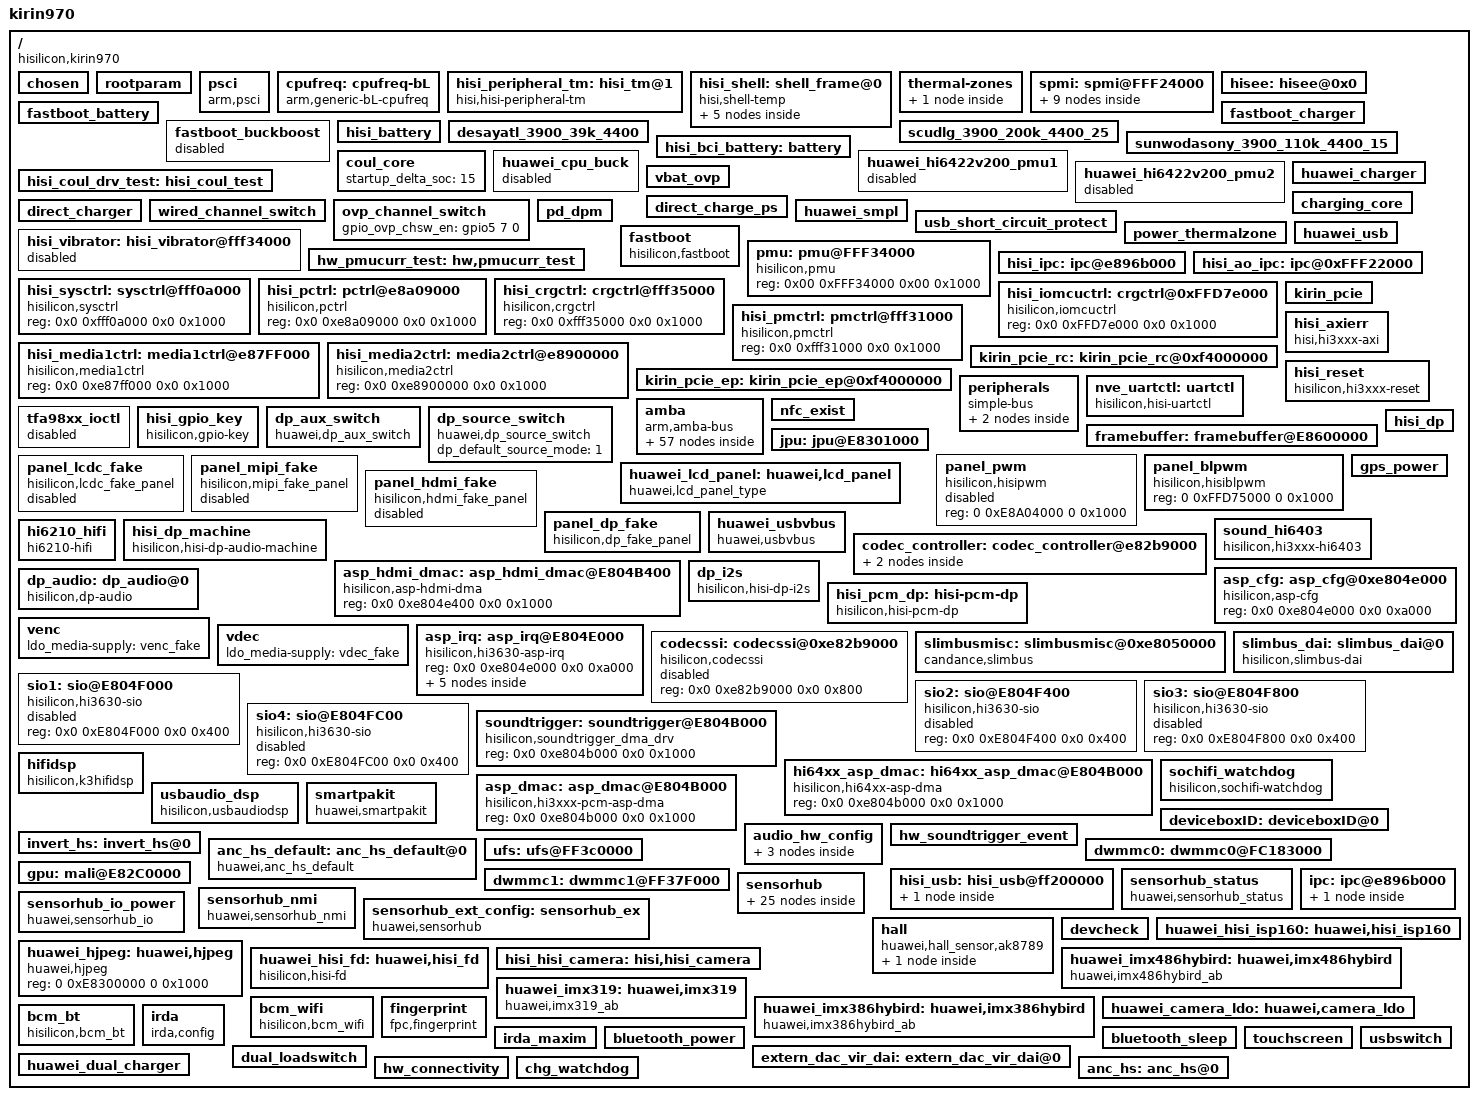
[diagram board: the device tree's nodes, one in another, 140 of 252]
/**
 * Copyright (C) 2014 Hisilicon Ltd.
 *
 *  This program is free software; you can redistribute it and/or modify
 *  it under the terms of the GNU General Public License version 2 as
 *  publishhed by the Free Software Foundation.
 */

/dts-v1/;
/include/ "fastboot.dtsi"
/include/ "ALPS_TUGL_V1_CS_pin.dtsi"
/include/ "kirin970_cci.dtsi"
/include/ "kirin970_gic.dtsi"
/include/ "kirin970_timer.dtsi"
/include/ "kirin970_clock_cs.dtsi"
/include/ "kirin970_peri_dvfs_volt_cs.dtsi"
/include/ "kirin970_peri_dvfs_cs.dtsi"
/include/ "kirin970_isp_cs.dtsi"
/include/ "kirin970_powerip_cs.dtsi"
/include/ "hisi_freq_autodown.dtsi"
/include/ "kirin970.dtsi"
/include/ "kirin970_lowpm.dtsi"
/include/ "kirin970_i2c.dtsi"
/include/ "kirin970_gpio_cs.dtsi"
/include/ "kirin970_pinctrl_cs.dtsi"
/include/ "hisi_64xx_codec.dtsi"
/include/ "ALPS_TUGL_V1_CS_hi6402_pin.dtsi"
/include/ "huawei_pmucurr_test.dtsi"
/include/ "hisi_bci_battery.dtsi"
/include/ "hisi_battery.dtsi"
/include/ "huawei_charger.dtsi"
/include/ "hisi_coul_spmi.dtsi"
/include/ "kirin970_soft_isc.dtsi"
/include/ "fastboot_battery.dtsi"
/include/ "fastboot_charger.dtsi"
/include/ "usb_short_circuit_protect.dtsi"
/include/ "desayatl_3900_39k_4400.dtsi"
/include/ "scudlg_3900_200k_4400_25.dtsi"
/include/ "sunwodasony_3900_110k_4400_15.dtsi"
/include/ "kirin970_thermal.dtsi"
/include/ "kirin970_pd.dtsi"
/include/ "fastboot_charger.dtsi"
/include/ "hisi_power_ip_test.dtsi"
/include/ "kirin970_framebuffer.dtsi"
/include/ "hisi_6421v600_pmic_led_spmi.dtsi"
/include/ "kirin970_coresight.dtsi"
/include/ "hisi_rtc_spmi.dtsi"
/include/ "modem/hisi_modem_balong.dtsi"
/include/ "hisi_soundtrigger_event.dtsi"
/include/ "huawei_audio.dtsi"
/include/ "huawei_smartpa.dtsi"
/include/ "kirin970_noc.dtsi"
/include/ "huawei_gps.dtsi"
/include/ "kirin970_dma64.dtsi"
/include/ "kirin970_trustedcore.dtsi"
/include/ "kirin970_jpu.dtsi"
/include/ "kirin970_ics_cs.dtsi"
/include/ "lcdkit/default/devkit_lcd.dtsi"
/include/ "lcdkit/alps_tugl/devkit_lcd.dtsi"
/include/ "kirin970_perfstat_cs.dtsi"
/include/ "kirin970_cpu_cs.dtsi"
/include/ "huawei_connectivity.dtsi"
/include/ "huawei_devdetect.dtsi"
/include/ "huawei_hall_inputhub.dtsi"
/include/ "huawei_irda.dtsi"
/include/ "huawei_usbpd.dtsi"
/include/ "huawei_usb_vbus.dtsi"
/include/ "huawei_bluetooth.dtsi"
/include/ "hisi_sim_hotplug.dtsi"
/include/ "huawei_usbswitch.dtsi"
/include/ "huawei_bastet.dtsi"

/ {
	#address-cells = <2>;
	#size-cells = <2>;
	model = "kirin970";
	compatible = "hisilicon,kirin970";
	interrupt-parent = <&gic>;
	hisi,boardid = <6 4 1 0>;
	hisi,boardname = "ALPS_TUGL_V1_CS";
	hisi,modem_id = <0x39001400>;
	hisi,product_id = <0x39001400>;
	hisi,product_name = "ALPS-AL00";
	hisi,camera_arch_csudp = "platform_cs_udp";

	chosen: chosen {};

	rootparam: rootparam {
	};


	psci: psci {
                compatible      = "arm,psci";
        };

	/* cpufreq  device */
	cpufreq: cpufreq-bL {
		compatible = "arm,generic-bL-cpufreq";
		status = "ok";
	};

	hisi_peripheral_tm: hisi_tm@1 {
		compatible = "hisi,hisi-peripheral-tm";
		hisi,peripheral_sensors = <8>;

		hisi,detect_system_h_tm_chanel = <7>;
		hisi,detect_system_h_tm_ntc = "austin_hkadc_soc_temp_table";
		hisi,detect_system_h_tm_state = "enable";
		hisi,detect_system_h_throttling = <53>;
		hisi,detect_system_h_shutdown = <55>;
		hisi,detect_system_h_below_vr_min = <53>;
		hisi,detect_system_h_over_skin = <12>;

		hisi,detect_flash_led_tm_chanel = <3>;
		hisi,detect_flash_led_tm_ntc = "austin_hkadc_soc_temp_table";
		hisi,detect_flash_led_tm_state = "enable";

		hisi,detect_charger_tm_chanel = <5>;
		hisi,detect_charger_tm_ntc = "austin_hkadc_soc_temp_table";
		hisi,detect_charger_tm_state = "enable";

		hisi,detect_pa_0_tm_chanel = <4>;
		hisi,detect_pa_0_tm_ntc = "austin_hkadc_pa_temp_table";
		hisi,detect_pa_0_tm_state = "enable";

		hisi,detect_pa_1_tm_chanel = <9>;
		hisi,detect_pa_1_tm_ntc = "austin_hkadc_pa_temp_table";
		hisi,detect_pa_1_tm_state = "enable";

		hisi,detect_dcxo0_tm_chanel = <15>;
		hisi,detect_dcxo0_tm_ntc = "austin_hkadc_adc_temp_table";
		hisi,detect_dcxo0_tm_state = "enable";

		hisi,detect_shell_tm_chanel = <7>;
		hisi,detect_shell_tm_ntc = "austin_hkadc_soc_temp_table";
		hisi,detect_shell_tm_state = "disable";

		hisi,detect_charger1_tm_chanel = <4>;
		hisi,detect_charger1_tm_ntc = "austin_hkadc_soc_temp_table";
		hisi,detect_charger1_tm_state = "disable";
		status = "ok";
	};

	hisi_shell: shell_frame@0 {
		compatible = "hisi,shell-temp";
		interval = <5000>;
		bias = <50000>;
		count = <6>;
		status = "ok";

		sensors {
			sensor0 {
				type = "system_h";
				coef = "26648","15083","13218","12081","13207","30703";
			};
			sensor1 {
				type = "charger";
				coef = "-981","-1677","-1950","-1666","-3205","-6959";
			};
			sensor2 {
				type = "pa_0";
				coef = "1023","-674","-912","-179","534","3893";
			};
			sensor3 {
				type = "dcxo0";
				coef = "-3881","1540","1161","-1446","-3721","1465";
			};
		};
	};

    thermal-zones {
        board_thermal {
            status = "disabled";
        };
    };

	spmi: spmi@FFF24000 {
		pmic: pmic@0 {
			pmic_led: pmic_led@a0 {
				status = "ok";
			};

			pmic_rtc: pmic_rtc@a0 {
				status = "ok";
			};

			ponkey: ponkey@b1 {
				status = "ok";
			};

			pmic_mntn: pmic_mntn@a0 {
				status = "ok";
			};

			hi6421v600_coul_spmi: hi6421v600_coul_spmi@1 {
                                 status = "ok";
                        };
		};
		subpmic: subpmic@6 {
			gpios = <&gpio28 5 0>;
			pinctrl-names = "default", "idle";
			pinctrl-0 = <&gpio229_pmx_func &gpio229_cfg_func>;
			pinctrl-1 = <&gpio229_pmx_idle &gpio229_cfg_idle>;
		};
	};

	hisee: hisee@0x0 {
	};

	fastboot_battery: fastboot_battery {
		status = "ok";
	};

	fastboot_charger: fastboot_charger {
		status = "ok";
	};

	fastboot_buckboost: fastboot_buckboost{
		status = "disabled";
	};

	hisi_battery: hisi_battery {
		status = "ok";
	};
	desayatl_3900_39k_4400:desayatl_3900_39k_4400 {
	};
	scudlg_3900_200k_4400_25:scudlg_3900_200k_4400_25 {
	};
	sunwodasony_3900_110k_4400_15:sunwodasony_3900_110k_4400_15 {
	};
	hisi_bci_battery: battery {
		status = "ok";
	};

	coul_core: coul_core {
		status = "ok";
		startup_delta_soc = <15>;
	};

	huawei_cpu_buck: huawei_cpu_buck {
		status = "disabled";
	};

	huawei_hi6422v200_pmu1: huawei_hi6422v200_pmu1 {
		status = "disabled";
	};

	huawei_hi6422v200_pmu2: huawei_hi6422v200_pmu2 {
		status = "disabled";
	};

	hisi_coul_drv_test: hisi_coul_test {
		status = "ok";
	};

	huawei_charger: huawei_charger {
		status = "ok";
	};

	vbat_ovp: vbat_ovp {
		status = "ok";
	};

	charging_core: charging_core {
		status = "ok";
		iterm = <160>;
		iin_usb = <470>;
		ichg_usb = <500>;
		ichg_fcp = <3500>;
		iin_fcp = <2000>;
		ichg_ac = <2100>;
		iin_ac = <2000>;
		inductance_para =
			"-32767", "15", "1900", "0",
			"15", "32767", "1900", "0";
	};
	direct_charge_ps: direct_charge_ps {
		boost_5v_support_scp_power = <1>;
		bst_ctrl = <&gpio27 4 0>;
		is_need_bst_ctrl = <1>;
		status = "ok";
	};
	direct_charger: direct_charger{
		use_5A = <1>;
		volt_para =
			"4100", "5150", "4650",
			"4250", "4650", "2800",
			"4360", "2800", "1200";
		compensate_r = <20>;
		cc_cable_detect_enable = <1>;
		full_path_res_max = <140>;
		scp_work_on_charger = <1>;
		standard_cable_full_path_res_max = <200>;
		temp_para =
			"-32767", "10", "0",
			"10", "45", "5150",
			"45", "32767", "0";
		status = "ok";
	};
	wired_channel_switch: wired_channel_switch {
		status = "ok";
	};
	ovp_channel_switch: ovp_channel_switch {
		gpio_ovp_chsw_en = <&gpio5 7 0>;
		status = "ok";
	};
	huawei_smpl: huawei_smpl {
		status = "ok";
	};

	usb_short_circuit_protect: usb_short_circuit_protect {
		status = "ok";
	};

	power_thermalzone: power_thermalzone {
		status = "ok";
	};

	pd_dpm: pd_dpm {
		switch_manual_enable = <0>;
		uart_use_sbu = <1>;
		uart_rx_gpio = <&gpio4 5 0>;
		uart_tx_gpio = <&gpio4 6 0>;
		abnormal_cc_detection = <1>;
		status = "ok";
	};

	huawei_usb: huawei_usb {
		status = "ok";
	};

	hisi_vibrator: hisi_vibrator@fff34000 {
		status = "disabled";
	};

	fastboot: fastboot {
		compatible = "hisilicon,fastboot";
	};

	pmu: pmu@FFF34000 {
		compatible = "hisilicon,pmu";
		reg = <0x00 0xFFF34000 0x00 0x1000>;
		status = "ok";
	};

	hw_pmucurr_test: hw,pmucurr_test {
		status = "ok";
	};

	hisi_ipc: ipc@e896b000 {
		status = "ok";
	};

	hisi_ao_ipc: ipc@0xFFF22000 {
		status = "ok";
	};

        hisi_sysctrl: sysctrl@fff0a000 {
                compatible = "hisilicon,sysctrl";
                reg = <0x0 0xfff0a000 0x0 0x1000>;
                status = "ok";
        };

        hisi_pctrl: pctrl@e8a09000 {
                compatible = "hisilicon,pctrl";
                reg = <0x0 0xe8a09000 0x0 0x1000>;
                status = "ok";
        };

        hisi_crgctrl: crgctrl@fff35000 {
                compatible = "hisilicon,crgctrl";
                reg = <0x0 0xfff35000 0x0 0x1000>;
                status = "ok";
        };

        hisi_iomcuctrl: crgctrl@0xFFD7e000 {
                compatible = "hisilicon,iomcuctrl";
                reg = <0x0 0xFFD7e000 0x0 0x1000>;
                status = "ok";
	};

        hisi_pmctrl: pmctrl@fff31000 {
                compatible = "hisilicon,pmctrl";
                reg = <0x0 0xfff31000 0x0 0x1000>;
                status = "ok";
        };

        hisi_media1ctrl: media1ctrl@e87FF000 {
                compatible = "hisilicon,media1ctrl";
                reg = <0x0 0xe87ff000 0x0 0x1000>;
                status = "ok";
        };

        hisi_media2ctrl: media2ctrl@e8900000 {
                compatible = "hisilicon,media2ctrl";
                reg = <0x0 0xe8900000 0x0 0x1000>;
                status = "ok";
        };

	kirin_pcie: kirin_pcie {
	};

	kirin_pcie_rc: kirin_pcie_rc@0xf4000000 {
		reg =  <0x0 0xf4000000 0x0 0x1000000>, <0x0 0xfc180000 0x0 0x1000>, <0x0 0xfc000000 0x0 0x80000>, <0x0 0xF4000000 0 0x2000>;
		wl_power = <51>;
		status = "ok";
	};

	kirin_pcie_ep: kirin_pcie_ep@0xf4000000 {
		reg =  <0x0 0xf4000000 0x0 0x1000000>, <0x0 0xfc180000 0x0 0x1000>, <0x0 0xfc000000 0x0 0x80000>, <0x0 0xF4000000 0 0x2000>;
	};

	hisi_axierr: hisi_axierr {
	        compatible = "hisi,hi3xxx-axi";
	        status = "ok";
        };

	hisi_reset: hisi_reset {
            compatible = "hisilicon,hi3xxx-reset";
            status = "ok";
        };

	peripherals: peripherals {
		compatible = "simple-bus";
		ranges = <0x0 0x00000000 0x0 0xffffffff>;

		clk6250khz: clk6250khz {
			compatible = "fixed-clock";
		};
/*
		clk4800khz: clk4800khz {
			compatible = "fixed-clock";
		};
*/
		dma0: dma@fdf30000 {
			status = "ok";
		};

	};

	nve_uartctl: uartctl {
		compatible = "hisilicon,hisi-uartctl";
	};

	amba: amba {
		compatible = "arm,amba-bus";
		ranges;

		/*rtc0: rtc@FFF04000 {
				compatible = "arm,rtc-pl031", "arm,primecell";
				reg = <0xfff04000 0x1000>;
				status = "ok";
		};*/

		/*rtc1: rtc@FFF05000 {
				compatible = "arm,rtc-pl031", "arm,primecell";
				reg = <0xfff05000 0x1000>;
				status = "ok";
		};*/

		watchdog0 {
			compatible = "arm,sp805", "arm,primecell";
			reg = <0x0 0xe8a06000 0x0 0x1000>;
			default-timeout = <24>;
			interrupts = <0 44 4>;
			clocks = <&pclk_gate_wd0 &pclk>;
			clock-names = "pclk_wd0", "apb_pclk";
			status = "ok";
		};

                iomcu_watchdog: watchdog@ffd7c000{
                        compatible = "hisilicon,iomcu-watchdog";
                        reg = <0x0 0xFFD7C000 0x0 0x1000>;
                        status = "ok";
                };

		/*wdt1@e8a07000 {
			compatible = "arm,sp805", "arm,primecell";
			reg = <0x0 0xe8a07000 0x0 0x1000>;
		};*/

		serial0: uart@fdf02000 {
			status = "ok";
		};

		serial1: uart@fdf00000 {
			status = "disabled";
		};

		serial2: uart@fdf03000 {
			status = "ok";
		};

		serial3: uart@ffd74000 {
			status = "disabled";
		};

		serial4: uart@fdf01000 {
			status = "ok";
		};

		serial5: uart@fdf05000 {
			status = "ok";
		};

		serial6: uart@fff32000 {
			status = "ok";
		};

		dx_cc63p: dx_cc63p@fdf0e000 {
			compatible = "dx,cc63p";
			reg = <0x0 0xfdf0e000 0x0 0x1000>;
			status = "ok";
		};

		spi0: spi@ffd70000 {
			status = "disabled";

			spi_dev0: spi_dev0@0 {
					compatible = "spi_dev0";
					reg = <0>;
			};

			spi_dev1: spi_dev1@1 {
					compatible = "spi_dev1";
					reg = <1>;
			};

			spi_dev2: spi_dev2@2 {
					compatible = "spi_dev2";
					reg = <2>;
			};

			spi_dev3: spi_dev3@3 {
					compatible = "spi_dev3";
					reg = <3>;
			};
		};

		spi1: spi@fdf08000 {
			status = "disabled";

			spi_dev10: spi_dev10@10 {
					compatible = "spi_dev10";
					reg = <0>;
			};
		};

		spi3: spi@fff2a000 {
			status = "ok";
			hardware-mutex = <0x01>;
			smc-flag = <1>;
			clock-rate = <83000000>;
			pinctrl-names = "default", "idle";
			pinctrl-0 = <&gpio144_pmx_func &gpio145_pmx_func &gpio146_pmx_func &gpio144_cfg_func &gpio145_cfg_func
					&gpio146_cfg_func>;
			pinctrl-1 = <&gpio144_pmx_idle &gpio145_pmx_idle &gpio146_pmx_idle &gpio144_cfg_idle &gpio145_cfg_idle
					&gpio146_cfg_idle>;
			huawei_thp: huawei_thp@10 {
					compatible = "huawei,thp";
					reg = <0>;

					thp_input_dev {
						compatible = "huawei,thp_input";
					};

					novatech {
					};

					rohm-bu21150 {
					};
			};

			spi_dev30: spi_dev30@30 {
					compatible = "spi_dev30";
					reg = <0>;
			};

			spi_dev31: spi_dev31@31 {
					compatible = "spi_dev31";
					reg = <1>;
			};

			spi_dev32: spi_dev32@32 {
					compatible = "spi_dev32";
					reg = <2>;
			};

			spi_dev33: spi_dev33@33 {
					compatible = "spi_dev33";
					reg = <3>;
			};
		};
		/* I2C0 ~ I2C4 */
		i2c0: i2c@FFD71000 {
			status = "disabled";
		};

		i2c1: i2c@FFD72000 {
			status = "ok";

			fusb30x_i2c1@22 {
				status = "ok";
			};

			rt1711_i2c1@4e {
				status = "ok";
			};

			tusb422_i2c1@20 {
				status = "ok";
			};

			rt9748: rt9748@67 {
				compatible = "rt9748";
				reg = <0x67>;
				status = "ok";
			};
		};

		i2c2: i2c@FFD73000 {
			status = "disabled";
		};

		i2c3: i2c@FDF0C000 {
			status = "ok";

			ti,lm36923{
				compatible = "ti,lm36923","ti,lm36923_i2c3";
				reg = <0x36>;
				status = "ok";
			};

			max77813: max77813@18 {
				compatible = "max77813";
				status = "disabled";
			};

			huawei,vl53l0@29 {
				compatible = "huawei,vl53l0_970";
				reg = <0x29>;
				status = "ok";
			};
		};

		i2c4: i2c@FDF0D000 {
			status = "ok";

			ti-drv2605@5a {
				status = "ok";
				reg = <0x5a>;
				compatible = "ti,drv2605";
			};

			tfa9872_smartpa_l: smartpa@35 {
				compatible = "huawei,smartpakit_i2c";
				status = "ok";

				hw_reset {
				};

				irq_handler {
				};

				regmap_cfg {
				};
			};

			tfa9872_smartpa_r: smartpa@36 {
				compatible = "huawei,smartpakit_i2c";
				status = "ok";

				hw_reset {
				};

				irq_handler {
				};

				regmap_cfg {
				};
			};

			pn547_nfc: nfc@28 {
				status = "ok";
				reg = <0x28>;
				compatible = "hisilicon,pn547_nfc";
			};

			huawei,lm3646@67 {
				status = "ok";
			};

			huawei,mp3336@27 {
				status = "ok";
			};

			tps65132_phy: tps65132@3e {
				status = "ok";
				reg = <0x3e>;
				compatible = "huawei,hw_tps65132";
			};

			lv52134a_phy: lv52134a@42 {
				status = "ok";
				reg = <0x42>;
				compatible = "huawei,hw_lv52134a";
			};

			rt4801h_phy: rt4801h@73 {
				status = "ok";
				reg = <0x73>;
				compatible = "huawei,hw_rt4801h";
			};
		};

		i2c6: i2c@FFD6A000 {
			status = "ok";
			hi6523_charger_i2c6: hi6523_charger_i2c6@6B {
				status = "ok";
				fcp_support = <1>;
				scp_support = <1>;
				vclamp = <150>;
				bat_comp = <30>;
				gpio_int = <&gpio18 6 0>;
				ico_current_mode = <0>;
			};
			fairchild_fsa9685_i2c6: fsa9685_i2c6@25{
				usbid-enable = <0>;
				scp_support = <1>;
				fairchild_fsa9685,gpio-intb = <&gpio28 3 0>;
				status = "disabled";
			};
		};

		i2c7: i2c@FDF0B000 {
			status = "ok";
		};
	};
	/* end amba */

	nfc_exist: nfc_exist {
		status = "ok";
	};

	tfa98xx_ioctl: tfa98xx_ioctl {
		status = "disabled";
	};

	hisi_gpio_key: hisi_gpio_key {
		compatible = "hisilicon,gpio-key";
		status = "ok";
	};

	dp_aux_switch: dp_aux_switch {
	        compatible = "huawei,dp_aux_switch";
	        status = "ok";
	};

	/*set dp source default mode*/
	dp_source_switch {
	        compatible = "huawei,dp_source_switch";
		dp_default_source_mode = <1>; /*0:diff mode 1:same mode*/
	        status = "ok";
	};

	/* display start */
	framebuffer: framebuffer@E8600000 {
	};

	/*jpeg decode */
	jpu: jpu@E8301000 {
	};

	panel_pwm: panel_pwm {
		compatible = "hisilicon,hisipwm";
		reg = <0 0xE8A04000 0 0x1000>;
		status = "disabled";
	};

	panel_blpwm: panel_blpwm {
		compatible = "hisilicon,hisiblpwm";
		reg = <0 0xFFD75000 0 0x1000>;
		status = "ok";
	};

	panel_lcdc_fake: panel_lcdc_fake {
		compatible = "hisilicon,lcdc_fake_panel";
		status = "disabled";
	};

	panel_mipi_fake: panel_mipi_fake {
		compatible = "hisilicon,mipi_fake_panel";
		status = "disabled";
	};

	huawei_lcd_panel: huawei,lcd_panel {
		compatible = "huawei,lcd_panel_type";
	};

	panel_hdmi_fake: panel_hdmi_fake {
		compatible = "hisilicon,hdmi_fake_panel";
		status = "disable";
	};

	panel_dp_fake: panel_dp_fake {
		compatible = "hisilicon,dp_fake_panel";
		status = "ok";
	};

	hisi_dp {
		status = "ok";
	};

	huawei_usbvbus: huawei_usbvbus {
		compatible = "huawei,usbvbus";
		status = "ok";
	};

	/* display end */

	/* audio device beg */
	codec_controller: codec_controller@e82b9000 {
		slimbusclk_io_driver = <0x2>;
		slimbusdata_io_driver = <0x2>;
		status = "ok";

		hi64xx_irq: hi64xx_irq@0 {
			status = "ok";

			hi6403_codec: hi6403_codec@0{
				status = "ok";
			};
		};
	};

	gps_power: gps_power{
		status = "ok";
	};

	sound_hi6403: sound_hi6403 {
		compatible = "hisilicon,hi3xxx-hi6403";
		status = "ok";
	};

	hi6210_hifi: hi6210_hifi {
		compatible = "hi6210-hifi";
		status = "ok";
	};

	hisi_dp_machine: hisi_dp_machine {
		compatible = "hisilicon,hisi-dp-audio-machine";
		status = "ok";
	};

	asp_hdmi_dmac: asp_hdmi_dmac@E804B400 {
		compatible = "hisilicon,asp-hdmi-dma";
		reg = <0x0 0xe804e400 0x0 0x1000>;
		status = "ok";
	};

	asp_cfg: asp_cfg@0xe804e000 {
		compatible = "hisilicon,asp-cfg";
		reg = <0x0 0xe804e000 0x0 0xa000>;
		status = "ok";
	};

	dp_i2s: dp_i2s {
		compatible = "hisilicon,hisi-dp-i2s";
		status = "ok";
        };

	dp_audio: dp_audio@0 {
		compatible = "hisilicon,dp-audio";
		status = "ok";
        };

	hisi_pcm_dp: hisi-pcm-dp {
		compatible = "hisilicon,hisi-pcm-dp";
		status = "ok";
	};
	venc {
		ldo_media-supply = <&venc_fake>;
	};
	vdec {
		ldo_media-supply = <&vdec_fake>;
	};
	asp_irq: asp_irq@E804E000 {
		compatible = "hisilicon,hi3630-asp-irq";
		reg = <0x0 0xe804e000 0x0 0xa000>;

		asp_common@0 {
			compatible = "hisilicon,hi3630-asp-common";
		};

		asp_srcup_normal@0 {
			compatible = "hisilicon,hi3630-srcup-normal";
		};

		asp_srcup_dsp@0 {
			compatible = "hisilicon,hi3630-srcup-dsp";
		};

		asp_srcdown@0 {
			compatible = "hisilicon,hi3630-srcdown";
		};

		asp_hdmi@0 {
			compatible = "hisilicon,hi3630-pcm-hdmi";
		};
	};

	codecssi: codecssi@0xe82b9000 {
		compatible = "hisilicon,codecssi";
		reg = <0x0 0xe82b9000 0x0 0x800>;
		status = "disabled";
	};

	slimbusmisc: slimbusmisc@0xe8050000 {
		compatible = "candance,slimbus";
		reg = <0x0 0xe8050000 0x0 0xb00>,
			<0x0 0xe804e000 0x0 0xa000>,
			<0x0 0xfff0a000 0x0 0x1000>;
		interrupts = <0x0 0x96 0x4>;
		interrupt-names = "asp_irq_slimbus";
		slimbus-reg-supply = <&asp>;
		pinctrl-names = "default", "idle";
		pinctrl-0 = <&gpio192_pmx_func
				&gpio193_pmx_func
				&gpio192_cfg_func
				&gpio193_cfg_func>;
		pinctrl-1 = <&gpio192_pmx_idle
				&gpio193_pmx_idle
				&gpio192_cfg_idle
				&gpio193_cfg_idle>;
		slimbus-ssi-sel = "slimbus";
		asp_power_state_offset = <0x06c>;
		slimbusclk_offset = <0x038>;
		slimbusdata_offset = <0x03c>;
		slimbusclk_cfg_offset = <0x864>;
		slimbusdata_cfg_offset = <0x868>;
		platform-type   = "ASIC";
		codec-type = "slimbus-6403cs";
		clk_asp_subsys = <415000>;
		slimbus_dynamic_freq= "true";
		pm_runtime_support;
		status = "ok";
	};

	slimbus_dai: slimbus_dai@0 {
		compatible = "hisilicon,slimbus-dai";
		status = "ok";
	};

	sio1: sio@E804F000 {
		compatible = "hisilicon,hi3630-sio";
		reg = <0x0 0xE804F000 0x0 0x400>;
		status = "disabled";
	};

	sio2: sio@E804F400 {
		compatible = "hisilicon,hi3630-sio";
		reg = <0x0 0xE804F400 0x0 0x400>;
		status = "disabled";
	};

	sio3: sio@E804F800 {
		compatible = "hisilicon,hi3630-sio";
		reg = <0x0 0xE804F800 0x0 0x400>;
		status = "disabled";
	};

	sio4: sio@E804FC00 {
		compatible = "hisilicon,hi3630-sio";
		reg = <0x0 0xE804FC00 0x0 0x400>;
		status = "disabled";
	};

	soundtrigger: soundtrigger@E804B000 {
		compatible = "hisilicon,soundtrigger_dma_drv";
		reg = <0x0 0xe804b000 0x0 0x1000>;
		status = "ok";
	};

	hi64xx_asp_dmac: hi64xx_asp_dmac@E804B000 {
		compatible = "hisilicon,hi64xx-asp-dma";
		reg = <0x0 0xe804b000 0x0 0x1000>;
		status = "ok";
	};

	hifidsp: hifidsp {
		compatible = "hisilicon,k3hifidsp";
		status = "ok";
	};

	sochifi_watchdog: sochifi_watchdog {
		compatible = "hisilicon,sochifi-watchdog";
		status = "ok";
	};

	asp_dmac: asp_dmac@E804B000 {
		compatible = "hisilicon,hi3xxx-pcm-asp-dma";
		reg = <0x0 0xe804b000 0x0 0x1000>;
		status = "ok";
	};

	usbaudio_dsp: usbaudio_dsp {
		compatible = "hisilicon,usbaudiodsp";
		status = "ok";
	};

	deviceboxID: deviceboxID@0 {
		status = "ok";
	};

	smartpakit: smartpakit {
		compatible = "huawei,smartpakit";
		status = "ok";
	};

	audio_hw_config: audio_hw_config {
		status = "ok";

		hifi_info {
		};

		hardware_info {
			status = "ok";
		};

		audio_capability {
		};
	};

	hw_soundtrigger_event: hw_soundtrigger_event {
		status = "ok";
	};

	invert_hs: invert_hs@0 {
		status = "ok";
	};

	anc_hs_default: anc_hs_default@0{
		compatible = "huawei,anc_hs_default";
		status = "ok";
	};

	/* audio device end */

	/*bootdevice: bootdevice {
	};*/

	/* UFS */
	ufs: ufs@FF3c0000 {
		status = "ok";
	};

	/* eMMC 4.5 */
	dwmmc0: dwmmc0@FC183000 {
	};

	/* SD */
	dwmmc1: dwmmc1@FF37F000 {
		status = "ok";
	};

	/* sdio */
	/*
	dwmmc2: dwmmc2@FC183000 {
		status = "disabled";
	};
	*/
	hisi_usb: hisi_usb@ff200000 {
		usb_ldo_disable = <1>;
		usb_aclk_freq = <238000000>;
		usb_support_dp = <1>;

		eye_diagram_param = <0x23DE7E7>;
		eye_diagram_host_param = <0x33DE7E7>;
		usb_support_check_voltage = <0x1>;
		set_hi_impedance = <0x0>;
		dwc3@ff100000 {
		};
	};

	gpu: mali@E82C0000 {
		status = "ok";
	};

	sensorhub_status: sensorhub_status {
		compatible = "huawei,sensorhub_status";
		status= "ok";
	};

	ipc: ipc@e896b000 {	/* add for fpga because iom7 start too slow锛?300ms锛?*/
		mailbox-10 {
		};
	};

	sensorhub_nmi: sensorhub_nmi {
		compatible = "huawei,sensorhub_nmi";
	};

	sensorhub: sensorhub {
		als_sensor: light {
			als1 {
				compatible="huawei,rohm_bh1745";
				reg=<0x38>;
				status = "ok";
			};

			als2 {
				compatible="huawei,avago_apds9251";
				reg=<0x52>;
				status = "ok";
			};
		};

		ps_sensor: proximity {
			ps1 {
				compatible="huawei,txc-pa224";
				reg=<0x1e>;
				status = "ok";
			};

			ps2 {
				compatible="huawei,avago-apds9110";
				reg=<0x53>;
				status = "ok";
			};

		};

		acc_sensor: gsensor {
			acc1 {
				compatible ="huawei,st-lsm6dsm";
				reg =<0x6a>;
				status = "ok";
			};

			acc2 {
				compatible ="huawei,invensense-icm20690";
				reg =<0x68>;
				status = "ok";
			};
		};

		gyro_sensor: gyroscope {
			gyro1 {
				compatible ="huawei,st-lsm6dsm";
				reg =<0x6a>;
				status = "ok";
			};

			gyro2 {
				compatible ="huawei,inv-icm20690";
				reg =<0x68>;
				status = "ok";
			};
		};

		mag_sensor: compass {
			mag1 {
				compatible="huawei,akm-akm09911";
				reg=<0x0d>;
				status = "ok";
			};

			mag2 {
				compatible="huawei,yamaha-yas537";
				reg=<0x2E>;
				status = "ok";
			};

			mag3 {
				compatible="huawei,akm-akm09918";
				reg=<0x0C>;
				status = "ok";
			};
		};

		airpress_sensor: airpress {
			airpress1 {
				compatible="huawei,st_lps22bh";
				reg=<0x5d>;
				status = "ok";
			};

			airpress2 {
				compatible="huawei,bosch_bmp380";
				reg=<0x77>;
				status = "ok";
			};
		};

		fingerprint_sensor: fingerprint {
			finger1 {
				compatible="fpc,fpc1262";
				reg=<0x0>;
				status = "ok";
			};

			finger2 {
				compatible="goodix,goodix5296";
				reg=<0x0>;
				status = "ok";
			};

			finger3 {
				compatible="silead,silead6275";
				reg=<0x0>;
				status = "ok";
			};
		};

		sar_sensor: sar {
			sar1 {
				compatible="huawei,semtech-sx9323";
				reg=<0x28>;
				status = "disabled";
			};
		};
	};

	sensorhub_ext_config: sensorhub_ex {
		compatible = "huawei,sensorhub";
	};

	sensorhub_io_power: sensorhub_io_power {
		compatible = "huawei,sensorhub_io";
		status="ok";
	};

	hall: hall {
		compatible = "huawei,hall_sensor,ak8789";
		status = "ok";

		huawei,hall_0 {
		};
	};
	/*
		device check : the 0 means that it don't need to check;
			the 1 means that it check at board check and running test;
			the 2 means that it check at running test
	*/
	devcheck: devcheck {
		touch_panel = <2>;
		compass = <1>;
		g_sensor = <1>;
		gyroscope = <1>;
		nfc = <1>;
		dc_dc = <1>;
		tps = <1>;
		l_sensor = <2>;
		charge = <1>;
		usb_switch = <0>;
		wifi = <1>;
		bt = <1>;
		gps = <1>;
		antenna_ctl = <0>;
		airpress = <1>;
		vibrator_lra = <1>;
		charge_loadswitch = <1>;
		laser = <1>;
		status = "ok";
	};

	huawei_hisi_isp160: huawei,hisi_isp160 {
                status = "ok";
	};

	huawei_hjpeg: huawei,hjpeg {
		compatible = "huawei,hjpeg";
		reg = <0 0xE8300000 0 0x1000>;
		status = "ok";
	};

	huawei_hisi_fd: huawei,hisi_fd {
		compatible = "hisilicon,hisi-fd";
		reg = <0x0 0xE8340000 0x0 0x20000>,    //FD reg
		      <0x0 0xE8320000 0x0 0x20000>,    //smmu reg
		      <0x0 0xE8303000 0x0 0x1000>;    //smmu master reg

		status = "ok";
	};

	hisi_hisi_camera: hisi,hisi_camera {
	};

	huawei_imx486hybird: huawei,imx486hybird {
		compatible = "huawei,imx486hybird_ab";
		status = "ok";
	};

	huawei_imx319: huawei,imx319 {
		compatible = "huawei,imx319_ab";
		status = "ok";
	};

	huawei_imx386hybird: huawei,imx386hybird {
		compatible = "huawei,imx386hybird_ab";
		status = "ok";
	};

	huawei_camera_ldo: huawei,camera_ldo {
	};

	bcm_wifi: bcm_wifi {
		compatible = "hisilicon,bcm_wifi";
		status = "ok";
	};

	bcm_bt: bcm_bt {
		compatible = "hisilicon,bcm_bt";
		status = "ok";
	};

	fingerprint: fingerprint {
		compatible = "fpc,fingerprint";
		spi-max-frequency = <5000000>;
		fingerprint,product = "alps";

		fingerprint,navigation_adjust1 = <1>;
		fingerprint,navigation_adjust2 = <0>;

		fingerprint,fpc2050 = <1>;
		fingerprint,reset_gpio = <211>;
		fingerprint,irq_gpio = <210>;
		fingerprint,cs_gpio = <216>;
		fingerprint,spi_num = <2>;
		fingerprint,force_storage_type = <1>;
		fingerprint,extern_ldo_name = "EXTERN_LDO";
		fingerprint,extern_ldo_num = <34>;
		fingreprint_ldo-supply = <&ldo34>;
		fingerprint,extern_vol = <3300000>;
		fingerprint,poweroff_when_pd_charge = <1>;
		pinctrl-names = "default", "idle";
	};

	irda: irda {
		compatible = "irda,config";
	};

	irda_maxim: irda_maxim {
		status = "ok";
	};

        bluetooth_power: bluetooth_power {
                status = "ok";
        };

        bluetooth_sleep: bluetooth_sleep {
                status = "ok";
        };

	
	spmi: spmi@FFF24000 {
		pmic: pmic@0 {
		      sim0 {
			      status = "ok";
		      };

		      sim1 {
			      status = "ok";
		      };
	      };
	};
	
	touchscreen: touchscreen {
	};
	extern_dac_vir_dai: extern_dac_vir_dai@0{
	};
	usbswitch: usbswitch{
	};
	dual_loadswitch: dual_loadswitch{
	};
	huawei_dual_charger: huawei_dual_charger{
	};
	hw_connectivity: hw_connectivity{
	};
	chg_watchdog: chg_watchdog {
	};
	anc_hs: anc_hs@0{
	};
};
